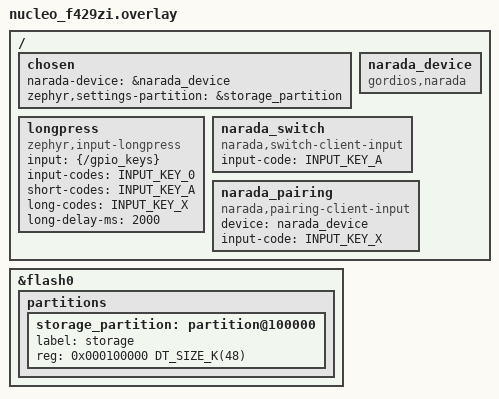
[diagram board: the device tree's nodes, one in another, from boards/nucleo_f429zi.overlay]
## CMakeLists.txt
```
# SPDX-License-Identifier: Apache-2.0

cmake_minimum_required(VERSION 3.20.0)

find_package(Zephyr REQUIRED HINTS $ENV{ZEPHYR_BASE})
project(coap_pairing)

target_sources(app PRIVATE src/switch.c)
```

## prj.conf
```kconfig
CONFIG_NETWORKING=y
CONFIG_JSON_LIBRARY=y

# Logging
CONFIG_LOG=y
CONFIG_LOG_MAX_LEVEL=1
CONFIG_LOG_MODE_MINIMAL=n
CONFIG_BOOT_BANNER=y
CONFIG_LOG_BACKEND_UART=y

# Kernel options
CONFIG_MAIN_STACK_SIZE=2560
CONFIG_INIT_STACKS=y

# CONFIG_NET_L2_OPENTHREAD=y
# CONFIG_OPENTHREAD_COAP=y
# CONFIG_OPENTHREAD_SLAAC=y
# 
# # Add features required for FTD CLI
# CONFIG_SHELL=y
# CONFIG_OPENTHREAD_SHELL=y
# CONFIG_OPENTHREAD_PING_SENDER=y
# 
# # Network config
# CONFIG_OPENTHREAD_PANID=4660
# CONFIG_OPENTHREAD_XPANID="11:11:11:11:22:22:22:22"
# CONFIG_OPENTHREAD_NETWORKKEY="00:11:22:33:44:55:66:77:88:99:aa:bb:cc:dd:ee:ff"
# CONFIG_OPENTHREAD_CHANNEL=15
# CONFIG_OPENTHREAD_NETWORK_NAME="OpenThreadDemo"

# SRP
CONFIG_MBEDTLS_HEAP_SIZE=8192

# CoAP utils
# CONFIG_COAP_UTILS=y
# CONFIG_COAP_PAIRING=y
# CONFIG_COAP_SWITCH=y

# Narada
CONFIG_NARADA=y
CONFIG_NARADA_SWITCH_CLIENT=y

CONFIG_NET_CONFIG_SETTINGS=y
CONFIG_NET_CONFIG_AUTO_INIT=y

CONFIG_EVENTS=y
CONFIG_SMF=y

CONFIG_FLASH=y
CONFIG_FLASH_MAP=y
CONFIG_NVS=y
CONFIG_SETTINGS=y
CONFIG_SETTINGS_NVS=y

CONFIG_SYSTEM_WORKQUEUE_STACK_SIZE=2048
```

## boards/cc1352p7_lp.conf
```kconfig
# FIXME
# This workaround the following issue with joiner:
# Join failed [Security]
CONFIG_OPENTHREAD_DEBUG=y
CONFIG_OPENTHREAD_LOG_LEVEL_INFO=y
# Add features required for FTD CLI
CONFIG_SHELL=y
CONFIG_OPENTHREAD_SHELL=y
CONFIG_OPENTHREAD_PING_SENDER=y

# OpenThread
CONFIG_NET_L2_OPENTHREAD=y
CONFIG_OPENTHREAD_COAP=y
CONFIG_OPENTHREAD_SLAAC=y

# Network config
CONFIG_OPENTHREAD_PANID=4660
CONFIG_OPENTHREAD_XPANID="11:11:11:11:22:22:22:22"
CONFIG_OPENTHREAD_NETWORKKEY="00:11:22:33:44:55:66:77:88:99:aa:bb:cc:dd:ee:ff"
CONFIG_OPENTHREAD_CHANNEL=15
CONFIG_OPENTHREAD_NETWORK_NAME="OpenThreadDemo"

CONFIG_NVS=y
```

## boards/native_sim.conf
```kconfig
CONFIG_GPIO=y

CONFIG_SHELL=y
CONFIG_NET_SHELL=y
CONFIG_NET_IPV4=y
CONFIG_NET_DHCPV4=y

CONFIG_COAP=y
CONFIG_COAP_CLIENT=y

CONFIG_NET_L2_ETHERNET=y
CONFIG_NATIVE_SIM_SLOWDOWN_TO_REAL_TIME=y
CONFIG_UART_NATIVE_PTY_0_ON_STDINOUT=y
CONFIG_PICOLIBC=y

# Enable only one protocol, if you enable both sources
# won't compile.
# IPv6 Support
#CONFIG_NET_IPV6=y
#CONFIG_NET_CONFIG_NEED_IPV6=y
#CONFIG_NET_CONFIG_MY_IPV6_ADDR="2001:db8::1"
#CONFIG_NET_IF_MCAST_IPV6_ADDR_COUNT=5

#IPv4 Support
CONFIG_NET_IPV4=y
CONFIG_NET_CONFIG_SETTINGS=y
CONFIG_NET_CONFIG_NEED_IPV4=y
CONFIG_NET_CONFIG_MY_IPV4_ADDR="192.0.2.3"

CONFIG_NET_SOCKETS=y
CONFIG_COAP=y
CONFIG_COAP_CLIENT=y
```

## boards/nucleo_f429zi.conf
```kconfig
CONFIG_SHELL=y
CONFIG_LOG_BACKEND_UART=n
CONFIG_NET_SHELL=y
CONFIG_NET_IPV4=y
CONFIG_NET_DHCPV4=y

CONFIG_COAP=y
CONFIG_COAP_CLIENT=y
CONFIG_NET_SOCKETS=y

CONFIG_LED=y

# Networking
CONFIG_NETWORKING=y
CONFIG_NET_UDP=y
CONFIG_NET_SOCKETS=y
CONFIG_NET_CONNECTION_MANAGER=y

CONFIG_INPUT=y
```

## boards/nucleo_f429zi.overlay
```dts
/ {
	chosen {
		narada-device = &narada_device;
		zephyr,settings-partition = &storage_partition;
	};

	longpress {
		input = <&{/gpio_keys}>;
		compatible = "zephyr,input-longpress";
		input-codes = <INPUT_KEY_0>;
		short-codes = <INPUT_KEY_A>;
		long-codes = <INPUT_KEY_X>;
		long-delay-ms = <2000>;
	};

	narada_device: narada_device {
		compatible = "gordios,narada";
		device_type = "switch";
	};

	narada_switch: narada_switch {
		compatible = "narada,switch-client-input";
		input-code = <INPUT_KEY_A>;
	};

	narada_pairing: narada_pairing {
		compatible = "narada,pairing-client-input";
		device = <&narada_device>;
		input-code = <INPUT_KEY_X>;
	};
};

&flash0 {
	partitions {
		/* Set 48KB of storage at the beginning of bank2 in order to have 3 sectors smaller than 32K
		 * 	(nvs.h: uint16_t sector_size)
		 */
		storage_partition: partition@100000 {
			label = "storage";
			reg = <0x000100000 DT_SIZE_K(48)>;
		};
	};
};
```

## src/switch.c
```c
#include <narada/narada.h>
#include <narada/pairing/client.h>
#include <narada/switch/client.h>

int main(void)
{
//	struct narada_client client;
//	struct narada_switch_client sw = {
//		.client = &client,
//	};
//	k_sem_init(&sw.coap_done_sem, 0, 1);
//	sw.id = 0;
//
//	k_sleep(K_MSEC(10000));
//	narada_init();
//	narada_client_init(&client);
	narada_run();
//	while (1)
//		if (narada_pairing_request(&client, NARADA_SWITCH_DEVICE))
//			k_sleep(K_MSEC(5000));
//	narada_client_init6(&client, "fd65:141e:2c57:1:da3b:9567:4192:c7ef", 5683);
//
//	while(1) {
//		narada_switch_set_state(&sw, 1);
//		k_sleep(K_MSEC(1000));
//
//		narada_switch_set_state(&sw, 0);
//		k_sleep(K_MSEC(1000));
//	}

	return 0;
}
```
